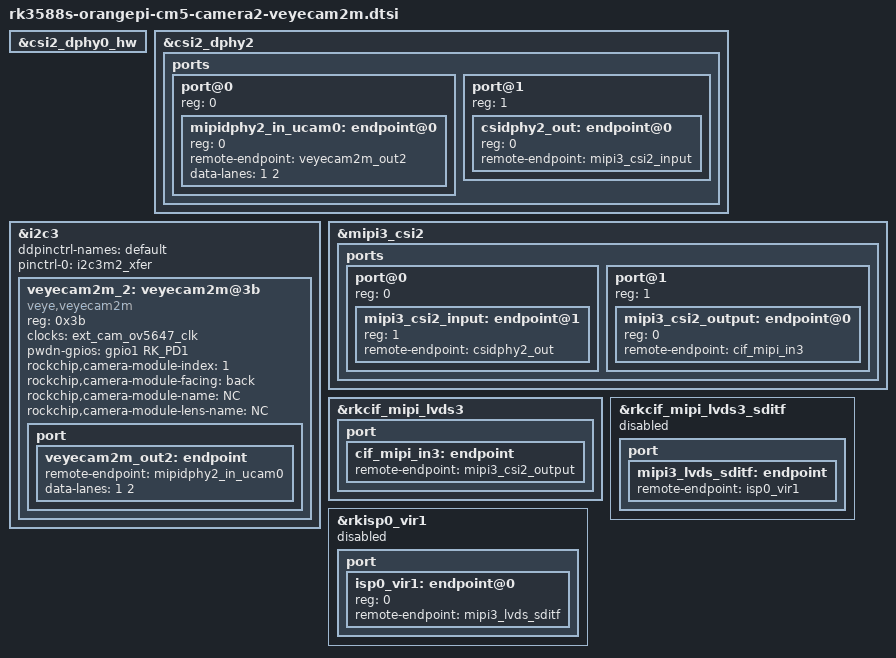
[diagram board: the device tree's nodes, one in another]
// SPDX-License-Identifier: (GPL-2.0+ OR MIT)
/*
 * Copyright (c) 2021 Rockchip Electronics Co., Ltd.
 *
 */

&csi2_dphy0_hw {
	status = "okay";
};

&csi2_dphy2 {
	status = "okay";
	ports {
		#address-cells = <1>;
		#size-cells = <0>;
		port@0 {
			reg = <0>;
			#address-cells = <1>;
			#size-cells = <0>;

			mipidphy2_in_ucam0: endpoint@0 {
				reg = <0>;
				remote-endpoint = <&veyecam2m_out2>;
				data-lanes = <1 2>;
			};

		};
		port@1 {
		        reg = <1>;
		        #address-cells = <1>;
		        #size-cells = <0>;
		        csidphy2_out: endpoint@0 {
		                reg = <0>;
		                remote-endpoint = <&mipi3_csi2_input>;
		        };
		};
	};
};

&i2c3 {
	status = "okay";
	ddpinctrl-names = "default";
	pinctrl-0 = <&i2c3m2_xfer>;

	veyecam2m_2: veyecam2m@3b{
		status = "okay";
        compatible = "veye,veyecam2m";
        reg = <0x3b>;
		clocks = <&ext_cam_ov5647_clk>;
		clock-names = "ext_cam_ov5647_clk";
		pwdn-gpios = <&gpio1 RK_PD1 GPIO_ACTIVE_HIGH>;
		rockchip,camera-module-index = <1>;
		rockchip,camera-module-facing = "back";
		rockchip,camera-module-name = "NC";
		rockchip,camera-module-lens-name = "NC";
		port {
			veyecam2m_out2: endpoint {
				remote-endpoint = <&mipidphy2_in_ucam0>;
				data-lanes = <1 2>;
			};
		};
	};


};

&mipi3_csi2 {
	status = "okay";
	ports {
		#address-cells = <1>;
		#size-cells = <0>;
		port@0 {
			reg = <0>;
			#address-cells = <1>;
			#size-cells = <0>;
			mipi3_csi2_input: endpoint@1 {
				reg = <1>;
				remote-endpoint = <&csidphy2_out>;
			};
		};
		port@1 {
			reg = <1>;
			#address-cells = <1>;
			#size-cells = <0>;
			mipi3_csi2_output: endpoint@0 {
				reg = <0>;
				remote-endpoint = <&cif_mipi_in3>;
			};
		};
	};
};



&rkcif_mipi_lvds3 {
	status = "okay";
	port {
		cif_mipi_in3: endpoint {
			remote-endpoint = <&mipi3_csi2_output>;
		};
	};
};


&rkcif_mipi_lvds3_sditf {
	status = "disabled";
	port {
		mipi3_lvds_sditf: endpoint {
			remote-endpoint = <&isp0_vir1>;
		};
	};
};



&rkisp0_vir1 {
	status = "disabled";
	port {
		#address-cells = <1>;
		#size-cells = <0>;
		isp0_vir1: endpoint@0 {
			reg = <0>;
			remote-endpoint = <&mipi3_lvds_sditf>;
		};
	};
};
